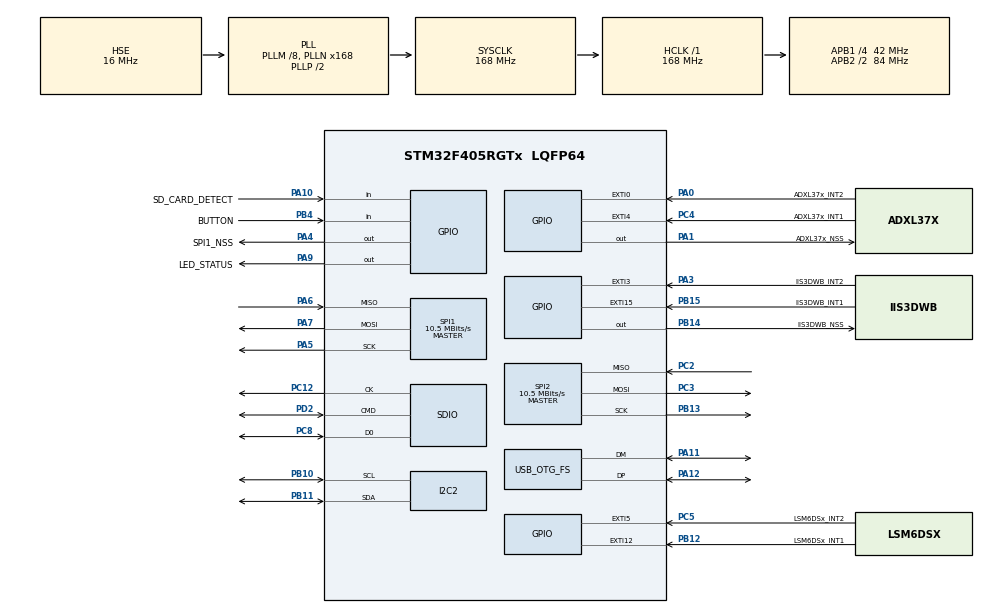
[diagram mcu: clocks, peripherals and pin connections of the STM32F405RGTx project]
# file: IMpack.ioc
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Dma.Request0=SDIO_RX
Dma.Request1=SDIO_TX
Dma.SDIO_RX.0.Direction=DMA_PERIPH_TO_MEMORY
Dma.SDIO_RX.0.FIFOMode=DMA_FIFOMODE_ENABLE
Dma.SDIO_RX.0.FIFOThreshold=DMA_FIFO_THRESHOLD_FULL
Dma.SDIO_RX.0.Instance=DMA2_Stream3
Dma.SDIO_RX.0.MemBurst=DMA_MBURST_INC4
Dma.SDIO_RX.0.MemDataAlignment=DMA_MDATAALIGN_WORD
Dma.SDIO_RX.0.MemInc=DMA_MINC_ENABLE
Dma.SDIO_RX.0.Mode=DMA_PFCTRL
Dma.SDIO_RX.0.PeriphBurst=DMA_PBURST_INC4
Dma.SDIO_RX.0.PeriphDataAlignment=DMA_PDATAALIGN_WORD
Dma.SDIO_RX.0.PeriphInc=DMA_PINC_DISABLE
Dma.SDIO_RX.0.Priority=DMA_PRIORITY_MEDIUM
Dma.SDIO_TX.1.Direction=DMA_MEMORY_TO_PERIPH
Dma.SDIO_TX.1.FIFOMode=DMA_FIFOMODE_ENABLE
Dma.SDIO_TX.1.FIFOThreshold=DMA_FIFO_THRESHOLD_FULL
Dma.SDIO_TX.1.Instance=DMA2_Stream6
Dma.SDIO_TX.1.MemBurst=DMA_MBURST_INC4
Dma.SDIO_TX.1.MemDataAlignment=DMA_MDATAALIGN_WORD
Dma.SDIO_TX.1.MemInc=DMA_MINC_ENABLE
Dma.SDIO_TX.1.Mode=DMA_PFCTRL
Dma.SDIO_TX.1.PeriphBurst=DMA_PBURST_INC4
Dma.SDIO_TX.1.PeriphDataAlignment=DMA_PDATAALIGN_WORD
Dma.SDIO_TX.1.PeriphInc=DMA_PINC_DISABLE
Dma.SDIO_TX.1.Priority=DMA_PRIORITY_MEDIUM
FATFS.BSP.number=1
FATFS.USE_DMA_CODE_SD=1
FATFS._FS_LOCK=0
FATFS0.BSP.STBoard=false
FATFS0.BSP.api=Unknown
FATFS0.BSP.instance=PA10
FATFS0.BSP.ip=GPIO
FATFS0.BSP.mode=Input
FATFS0.BSP.name=Detect_SDIO
FATFS0.BSP.solution=PA10
Mcu.Family=STM32F4
Mcu.Name=STM32F405RGTx
Mcu.Package=LQFP64
NVIC.DMA2_Stream3_IRQn=true\:2\:2\:true\:false\:true\:true\:true\:true
NVIC.DMA2_Stream6_IRQn=true\:2\:2\:true\:false\:true\:true\:true\:true
NVIC.EXTI15_10_IRQn=true\:0\:0\:true\:false\:true\:true\:true\:true
NVIC.EXTI4_IRQn=true\:0\:0\:true\:false\:true\:true\:true\:true
NVIC.EXTI9_5_IRQn=true\:0\:0\:true\:false\:true\:true\:true\:true
NVIC.PriorityGroup=NVIC_PRIORITYGROUP_2
NVIC.SDIO_IRQn=true\:2\:2\:true\:false\:true\:true\:true\:true
NVIC.TIM3_IRQn=true\:2\:2\:true\:false\:true\:true\:true\:true
PA0-WKUP.GPIO_Label=ADXL37x_INT2
PA0-WKUP.Signal=GPXTI0
PA1.GPIO_Label=ADXL37x_NSS
PA1.GPIO_Speed=GPIO_SPEED_FREQ_VERY_HIGH
PA1.PinState=GPIO_PIN_SET
PA1.Signal=GPIO_Output
PA10.GPIO_Label=SD_CARD_DETECT
PA10.Signal=GPIO_Input
PA11.Mode=Device_Only
PA11.Signal=USB_OTG_FS_DM
PA12.Mode=Device_Only
PA12.Signal=USB_OTG_FS_DP
PA13.Mode=Trace_Asynchronous_SW
PA13.Signal=SYS_JTMS-SWDIO
PA14.Mode=Trace_Asynchronous_SW
PA14.Signal=SYS_JTCK-SWCLK
PA3.GPIO_Label=IIS3DWB_INT2
PA3.Signal=GPXTI3
PA4.GPIO_Label=SPI1_NSS
PA4.GPIO_Speed=GPIO_SPEED_FREQ_VERY_HIGH
PA4.PinState=GPIO_PIN_SET
PA4.Signal=GPIO_Output
PA5.Mode=Full_Duplex_Master
PA5.Signal=SPI1_SCK
PA6.Mode=Full_Duplex_Master
PA6.Signal=SPI1_MISO
PA7.Mode=Full_Duplex_Master
PA7.Signal=SPI1_MOSI
PA9.GPIO_Label=LED_STATUS
PA9.PinState=GPIO_PIN_RESET
PA9.Signal=GPIO_Output
PB10.GPIO_Pu=GPIO_NOPULL
PB10.Mode=I2C
PB10.Signal=I2C2_SCL
PB11.GPIO_Pu=GPIO_NOPULL
PB11.Mode=I2C
PB11.Signal=I2C2_SDA
PB12.GPIO_Label=LSM6DSx_INT1
PB12.Signal=GPXTI12
PB13.Mode=Full_Duplex_Master
PB13.Signal=SPI2_SCK
PB14.GPIO_Label=IIS3DWB_NSS
PB14.GPIO_Speed=GPIO_SPEED_FREQ_VERY_HIGH
PB14.PinState=GPIO_PIN_SET
PB14.Signal=GPIO_Output
PB15.GPIO_Label=IIS3DWB_INT1
PB15.Signal=GPXTI15
PB3.Mode=Trace_Asynchronous_SW
PB3.Signal=SYS_JTDO-SWO
PB4.GPIO_Label=BUTTON
PB4.Signal=GPIO_Input
PC10.Signal=SDIO_D2
PC11.Signal=SDIO_D3
PC12.GPIO_PuPd=GPIO_NOPULL
PC12.Mode=SD_1_bit
PC12.Signal=SDIO_CK
PC2.Mode=Full_Duplex_Master
PC2.Signal=SPI2_MISO
PC3.Mode=Full_Duplex_Master
PC3.Signal=SPI2_MOSI
PC4.GPIO_Label=ADXL37x_INT1
PC4.Signal=GPXTI4
PC5.GPIO_Label=LSM6DSx_INT2
PC5.Signal=GPXTI5
PC8.GPIO_PuPd=GPIO_NOPULL
PC8.Mode=SD_1_bit
PC8.Signal=SDIO_D0
PC9.Signal=SDIO_D1
PD2.GPIO_PuPd=GPIO_NOPULL
PD2.Mode=SD_1_bit
PD2.Signal=SDIO_CMD
PH0-OSC_IN.Mode=HSE-External-Oscillator
PH0-OSC_IN.Signal=RCC_OSC_IN
PH1-OSC_OUT.Mode=HSE-External-Oscillator
PH1-OSC_OUT.Signal=RCC_OSC_OUT
ProjectManager.HeapSize=0x800
ProjectManager.StackSize=0x1600
ProjectManager.TargetToolchain=STM32CubeIDE
RCC.48MHZClocksFreq_Value=48000000
RCC.AHBFreq_Value=168000000
RCC.APB1CLKDivider=RCC_HCLK_DIV4
RCC.APB1Freq_Value=42000000
RCC.APB1TimFreq_Value=84000000
RCC.APB2CLKDivider=RCC_HCLK_DIV2
RCC.APB2Freq_Value=84000000
RCC.APB2TimFreq_Value=168000000
RCC.CortexFreq_Value=168000000
RCC.HCLKFreq_Value=168000000
RCC.HSE_VALUE=16000000
RCC.HSI_VALUE=16000000
RCC.LSE_VALUE=32768
RCC.PLLM=8
RCC.PLLN=168
RCC.PLLQ=7
RCC.SYSCLKFreq_VALUE=168000000
RCC.SYSCLKSource=RCC_SYSCLKSOURCE_PLLCLK
RCC.VCOOutputFreq_Value=336000000
SDIO.ClockBypass=SDIO_CLOCK_BYPASS_DISABLE
SDIO.ClockDiv=0
SPI1.BaudRatePrescaler=SPI_BAUDRATEPRESCALER_8
SPI1.CalculateBaudRate=10.5 MBits/s
SPI1.Direction=SPI_DIRECTION_2LINES
SPI1.Mode=SPI_MODE_MASTER
SPI1.VirtualType=VM_MASTER
SPI2.BaudRatePrescaler=SPI_BAUDRATEPRESCALER_4
SPI2.CalculateBaudRate=10.5 MBits/s
SPI2.Direction=SPI_DIRECTION_2LINES
SPI2.Mode=SPI_MODE_MASTER
SPI2.VirtualType=VM_MASTER
TIM2.Prescaler=83
TIM3.Period=840-1
USB_OTG_FS.VirtualMode=Device_Only
VP_FATFS_VS_SDIO.Mode=SDIO
VP_TIM2_VS_ClockSourceINT.Mode=Internal
VP_TIM3_VS_ClockSourceINT.Mode=Internal
board=custom

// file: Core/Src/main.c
/* USER CODE BEGIN Header */
/**
  ******************************************************************************
  * @file           : main.c
  * @brief          : Main program body
  ******************************************************************************
  * @attention
  *
  * Copyright (c) 2024 STMicroelectronics.
  * All rights reserved.
  *
  * This software is licensed under terms that can be found in the LICENSE file
  * in the root directory of this software component.
  * If no LICENSE file comes with this software, it is provided AS-IS.
  *
  ******************************************************************************
  */
/* USER CODE END Header */
#include "main.h"
#include "fatfs.h"

/* USER CODE BEGIN Includes */
#include "app.h"
/* USER CODE END Includes */

I2C_HandleTypeDef hi2c2;

SD_HandleTypeDef hsd;
DMA_HandleTypeDef hdma_sdio_rx;
DMA_HandleTypeDef hdma_sdio_tx;

SPI_HandleTypeDef hspi1;
SPI_HandleTypeDef hspi2;

TIM_HandleTypeDef htim2;
TIM_HandleTypeDef htim3;

PCD_HandleTypeDef hpcd_USB_OTG_FS;

void SystemClock_Config(void);
static void MX_GPIO_Init(void);
static void MX_DMA_Init(void);
static void MX_SPI1_Init(void);
static void MX_SDIO_SD_Init(void);
static void MX_SPI2_Init(void);
static void MX_TIM2_Init(void);
static void MX_I2C2_Init(void);
static void MX_TIM3_Init(void);
static void MX_USB_OTG_FS_PCD_Init(void);

/* USER CODE BEGIN 0 */
void HAL_GPIO_EXTI_Callback(uint16_t GPIO_Pin)
{
	App_PinInterrupt(GPIO_Pin);  /* call our application interrupt handler */
}

void HAL_TIM_PeriodElapsedCallback(TIM_HandleTypeDef* htim)
{
    App_TimerInterrupt();
}

/* USER CODE END 0 */

int main(void)
{

  /* MCU Configuration--------------------------------------------------------*/

  /* Reset of all peripherals, Initializes the Flash interface and the Systick. */
  HAL_Init();

  /* Configure the system clock */
  SystemClock_Config();

  /* Initialize all configured peripherals */
  MX_GPIO_Init();
  MX_DMA_Init();
  MX_SPI1_Init();
  MX_SDIO_SD_Init();
  MX_FATFS_Init();
  MX_SPI2_Init();
  MX_TIM2_Init();
  MX_I2C2_Init();
  MX_TIM3_Init();
  MX_USB_OTG_FS_PCD_Init();
  /* USER CODE BEGIN 2 */

  /* start the timer to measure sampling time */
  HAL_TIM_Base_Start(&htim2);

  /* set up our application */
  App_Setup(&hsd, &hspi1, &hspi2, &hspi2, &(TIM2->CNT));

  /* start the timer for the SPI communications thread */
  HAL_TIM_Base_Start_IT(&htim3);

  /* USER CODE END 2 */

  /* Infinite loop */
  /* USER CODE BEGIN WHILE */
  while (1)
  {

	App_Loop();

    /* USER CODE END WHILE */

  }
}

void SystemClock_Config(void)
{
  RCC_OscInitTypeDef RCC_OscInitStruct = {0};
  RCC_ClkInitTypeDef RCC_ClkInitStruct = {0};

  /** Configure the main internal regulator output voltage
  */
  __HAL_RCC_PWR_CLK_ENABLE();
  __HAL_PWR_VOLTAGESCALING_CONFIG(PWR_REGULATOR_VOLTAGE_SCALE1);

  /** Initializes the RCC Oscillators according to the specified parameters
  * in the RCC_OscInitTypeDef structure.
  */
  RCC_OscInitStruct.OscillatorType = RCC_OSCILLATORTYPE_HSE;
  RCC_OscInitStruct.HSEState = RCC_HSE_ON;
  RCC_OscInitStruct.PLL.PLLState = RCC_PLL_ON;
  RCC_OscInitStruct.PLL.PLLSource = RCC_PLLSOURCE_HSE;
  RCC_OscInitStruct.PLL.PLLM = 8;
  RCC_OscInitStruct.PLL.PLLN = 168;
  RCC_OscInitStruct.PLL.PLLP = RCC_PLLP_DIV2;
  RCC_OscInitStruct.PLL.PLLQ = 7;
  if (HAL_RCC_OscConfig(&RCC_OscInitStruct) != HAL_OK)
  {
    Error_Handler();
  }

  /** Initializes the CPU, AHB and APB buses clocks
  */
  RCC_ClkInitStruct.ClockType = RCC_CLOCKTYPE_HCLK|RCC_CLOCKTYPE_SYSCLK
                              |RCC_CLOCKTYPE_PCLK1|RCC_CLOCKTYPE_PCLK2;
  RCC_ClkInitStruct.SYSCLKSource = RCC_SYSCLKSOURCE_PLLCLK;
  RCC_ClkInitStruct.AHBCLKDivider = RCC_SYSCLK_DIV1;
  RCC_ClkInitStruct.APB1CLKDivider = RCC_HCLK_DIV4;
  RCC_ClkInitStruct.APB2CLKDivider = RCC_HCLK_DIV2;

  if (HAL_RCC_ClockConfig(&RCC_ClkInitStruct, FLASH_LATENCY_5) != HAL_OK)
  {
    Error_Handler();
  }
}

static void MX_I2C2_Init(void)
{

  hi2c2.Instance = I2C2;
  hi2c2.Init.ClockSpeed = 100000;
  hi2c2.Init.DutyCycle = I2C_DUTYCYCLE_2;
  hi2c2.Init.OwnAddress1 = 0;
  hi2c2.Init.AddressingMode = I2C_ADDRESSINGMODE_7BIT;
  hi2c2.Init.DualAddressMode = I2C_DUALADDRESS_DISABLE;
  hi2c2.Init.OwnAddress2 = 0;
  hi2c2.Init.GeneralCallMode = I2C_GENERALCALL_DISABLE;
  hi2c2.Init.NoStretchMode = I2C_NOSTRETCH_DISABLE;
  if (HAL_I2C_Init(&hi2c2) != HAL_OK)
  {
    Error_Handler();
  }

}

static void MX_SDIO_SD_Init(void)
{

  hsd.Instance = SDIO;
  hsd.Init.ClockEdge = SDIO_CLOCK_EDGE_RISING;
  hsd.Init.ClockBypass = SDIO_CLOCK_BYPASS_DISABLE;
  hsd.Init.ClockPowerSave = SDIO_CLOCK_POWER_SAVE_DISABLE;
  hsd.Init.BusWide = SDIO_BUS_WIDE_1B;
  hsd.Init.HardwareFlowControl = SDIO_HARDWARE_FLOW_CONTROL_DISABLE;
  hsd.Init.ClockDiv = 0;

}

static void MX_SPI1_Init(void)
{

  /* SPI1 parameter configuration*/
  hspi1.Instance = SPI1;
  hspi1.Init.Mode = SPI_MODE_MASTER;
  hspi1.Init.Direction = SPI_DIRECTION_2LINES;
  hspi1.Init.DataSize = SPI_DATASIZE_8BIT;
  hspi1.Init.CLKPolarity = SPI_POLARITY_LOW;
  hspi1.Init.CLKPhase = SPI_PHASE_1EDGE;
  hspi1.Init.NSS = SPI_NSS_SOFT;
  hspi1.Init.BaudRatePrescaler = SPI_BAUDRATEPRESCALER_8;
  hspi1.Init.FirstBit = SPI_FIRSTBIT_MSB;
  hspi1.Init.TIMode = SPI_TIMODE_DISABLE;
  hspi1.Init.CRCCalculation = SPI_CRCCALCULATION_DISABLE;
  hspi1.Init.CRCPolynomial = 10;
  if (HAL_SPI_Init(&hspi1) != HAL_OK)
  {
    Error_Handler();
  }

}

static void MX_SPI2_Init(void)
{

  /* SPI2 parameter configuration*/
  hspi2.Instance = SPI2;
  hspi2.Init.Mode = SPI_MODE_MASTER;
  hspi2.Init.Direction = SPI_DIRECTION_2LINES;
  hspi2.Init.DataSize = SPI_DATASIZE_8BIT;
  hspi2.Init.CLKPolarity = SPI_POLARITY_LOW;
  hspi2.Init.CLKPhase = SPI_PHASE_1EDGE;
  hspi2.Init.NSS = SPI_NSS_SOFT;
  hspi2.Init.BaudRatePrescaler = SPI_BAUDRATEPRESCALER_4;
  hspi2.Init.FirstBit = SPI_FIRSTBIT_MSB;
  hspi2.Init.TIMode = SPI_TIMODE_DISABLE;
  hspi2.Init.CRCCalculation = SPI_CRCCALCULATION_DISABLE;
  hspi2.Init.CRCPolynomial = 10;
  if (HAL_SPI_Init(&hspi2) != HAL_OK)
  {
    Error_Handler();
  }

}

static void MX_TIM2_Init(void)
{

  TIM_ClockConfigTypeDef sClockSourceConfig = {0};
  TIM_MasterConfigTypeDef sMasterConfig = {0};

  htim2.Instance = TIM2;
  htim2.Init.Prescaler = 83;
  htim2.Init.CounterMode = TIM_COUNTERMODE_UP;
  htim2.Init.Period = 4294967295;
  htim2.Init.ClockDivision = TIM_CLOCKDIVISION_DIV1;
  htim2.Init.AutoReloadPreload = TIM_AUTORELOAD_PRELOAD_DISABLE;
  if (HAL_TIM_Base_Init(&htim2) != HAL_OK)
  {
    Error_Handler();
  }
  sClockSourceConfig.ClockSource = TIM_CLOCKSOURCE_INTERNAL;
  if (HAL_TIM_ConfigClockSource(&htim2, &sClockSourceConfig) != HAL_OK)
  {
    Error_Handler();
  }
  sMasterConfig.MasterOutputTrigger = TIM_TRGO_RESET;
  sMasterConfig.MasterSlaveMode = TIM_MASTERSLAVEMODE_DISABLE;
  if (HAL_TIMEx_MasterConfigSynchronization(&htim2, &sMasterConfig) != HAL_OK)
  {
    Error_Handler();
  }

}

static void MX_TIM3_Init(void)
{

  TIM_ClockConfigTypeDef sClockSourceConfig = {0};
  TIM_MasterConfigTypeDef sMasterConfig = {0};

  htim3.Instance = TIM3;
  htim3.Init.Prescaler = 0;
  htim3.Init.CounterMode = TIM_COUNTERMODE_UP;
  htim3.Init.Period = 840-1;
  htim3.Init.ClockDivision = TIM_CLOCKDIVISION_DIV1;
  htim3.Init.AutoReloadPreload = TIM_AUTORELOAD_PRELOAD_DISABLE;
  if (HAL_TIM_Base_Init(&htim3) != HAL_OK)
  {
    Error_Handler();
  }
  sClockSourceConfig.ClockSource = TIM_CLOCKSOURCE_INTERNAL;
  if (HAL_TIM_ConfigClockSource(&htim3, &sClockSourceConfig) != HAL_OK)
  {
    Error_Handler();
  }
  sMasterConfig.MasterOutputTrigger = TIM_TRGO_RESET;
  sMasterConfig.MasterSlaveMode = TIM_MASTERSLAVEMODE_DISABLE;
  if (HAL_TIMEx_MasterConfigSynchronization(&htim3, &sMasterConfig) != HAL_OK)
  {
    Error_Handler();
  }

}

static void MX_USB_OTG_FS_PCD_Init(void)
{

  hpcd_USB_OTG_FS.Instance = USB_OTG_FS;
  hpcd_USB_OTG_FS.Init.dev_endpoints = 4;
  hpcd_USB_OTG_FS.Init.speed = PCD_SPEED_FULL;
  hpcd_USB_OTG_FS.Init.dma_enable = DISABLE;
  hpcd_USB_OTG_FS.Init.phy_itface = PCD_PHY_EMBEDDED;
  hpcd_USB_OTG_FS.Init.Sof_enable = DISABLE;
  hpcd_USB_OTG_FS.Init.low_power_enable = DISABLE;
  hpcd_USB_OTG_FS.Init.lpm_enable = DISABLE;
  hpcd_USB_OTG_FS.Init.vbus_sensing_enable = DISABLE;
  hpcd_USB_OTG_FS.Init.use_dedicated_ep1 = DISABLE;
  if (HAL_PCD_Init(&hpcd_USB_OTG_FS) != HAL_OK)
  {
    Error_Handler();
  }

}

static void MX_DMA_Init(void)
{

  /* DMA controller clock enable */
  __HAL_RCC_DMA2_CLK_ENABLE();

  /* DMA interrupt init */
  /* DMA2_Stream3_IRQn interrupt configuration */
  HAL_NVIC_SetPriority(DMA2_Stream3_IRQn, 2, 2);
  HAL_NVIC_EnableIRQ(DMA2_Stream3_IRQn);
  /* DMA2_Stream6_IRQn interrupt configuration */
  HAL_NVIC_SetPriority(DMA2_Stream6_IRQn, 2, 2);
  HAL_NVIC_EnableIRQ(DMA2_Stream6_IRQn);

}

static void MX_GPIO_Init(void)
{
  GPIO_InitTypeDef GPIO_InitStruct = {0};

  /* GPIO Ports Clock Enable */
  __HAL_RCC_GPIOH_CLK_ENABLE();
  __HAL_RCC_GPIOC_CLK_ENABLE();
  __HAL_RCC_GPIOA_CLK_ENABLE();
  __HAL_RCC_GPIOB_CLK_ENABLE();
  __HAL_RCC_GPIOD_CLK_ENABLE();

  /*Configure GPIO pin Output Level */
  HAL_GPIO_WritePin(GPIOA, ADXL37x_NSS_Pin|SPI1_NSS_Pin, GPIO_PIN_SET);

  /*Configure GPIO pin Output Level */
  HAL_GPIO_WritePin(IIS3DWB_NSS_GPIO_Port, IIS3DWB_NSS_Pin, GPIO_PIN_SET);

  /*Configure GPIO pin Output Level */
  HAL_GPIO_WritePin(LED_STATUS_GPIO_Port, LED_STATUS_Pin, GPIO_PIN_RESET);

  /*Configure GPIO pins : ADXL37x_INT2_Pin IIS3DWB_INT2_Pin */
  GPIO_InitStruct.Pin = ADXL37x_INT2_Pin|IIS3DWB_INT2_Pin;
  GPIO_InitStruct.Mode = GPIO_MODE_IT_RISING;
  GPIO_InitStruct.Pull = GPIO_NOPULL;
  HAL_GPIO_Init(GPIOA, &GPIO_InitStruct);

  /*Configure GPIO pins : ADXL37x_NSS_Pin SPI1_NSS_Pin */
  GPIO_InitStruct.Pin = ADXL37x_NSS_Pin|SPI1_NSS_Pin;
  GPIO_InitStruct.Mode = GPIO_MODE_OUTPUT_PP;
  GPIO_InitStruct.Pull = GPIO_NOPULL;
  GPIO_InitStruct.Speed = GPIO_SPEED_FREQ_VERY_HIGH;
  HAL_GPIO_Init(GPIOA, &GPIO_InitStruct);

  /*Configure GPIO pins : ADXL37x_INT1_Pin LSM6DSx_INT2_Pin */
  GPIO_InitStruct.Pin = ADXL37x_INT1_Pin|LSM6DSx_INT2_Pin;
  GPIO_InitStruct.Mode = GPIO_MODE_IT_RISING;
  GPIO_InitStruct.Pull = GPIO_NOPULL;
  HAL_GPIO_Init(GPIOC, &GPIO_InitStruct);

  /*Configure GPIO pins : LSM6DSx_INT1_Pin IIS3DWB_INT1_Pin */
  GPIO_InitStruct.Pin = LSM6DSx_INT1_Pin|IIS3DWB_INT1_Pin;
  GPIO_InitStruct.Mode = GPIO_MODE_IT_RISING;
  GPIO_InitStruct.Pull = GPIO_NOPULL;
  HAL_GPIO_Init(GPIOB, &GPIO_InitStruct);

  /*Configure GPIO pin : IIS3DWB_NSS_Pin */
  GPIO_InitStruct.Pin = IIS3DWB_NSS_Pin;
  GPIO_InitStruct.Mode = GPIO_MODE_OUTPUT_PP;
  GPIO_InitStruct.Pull = GPIO_NOPULL;
  GPIO_InitStruct.Speed = GPIO_SPEED_FREQ_VERY_HIGH;
  HAL_GPIO_Init(IIS3DWB_NSS_GPIO_Port, &GPIO_InitStruct);

  /*Configure GPIO pin : LED_STATUS_Pin */
  GPIO_InitStruct.Pin = LED_STATUS_Pin;
  GPIO_InitStruct.Mode = GPIO_MODE_OUTPUT_PP;
  GPIO_InitStruct.Pull = GPIO_NOPULL;
  GPIO_InitStruct.Speed = GPIO_SPEED_FREQ_LOW;
  HAL_GPIO_Init(LED_STATUS_GPIO_Port, &GPIO_InitStruct);

  /*Configure GPIO pin : SD_CARD_DETECT_Pin */
  GPIO_InitStruct.Pin = SD_CARD_DETECT_Pin;
  GPIO_InitStruct.Mode = GPIO_MODE_INPUT;
  GPIO_InitStruct.Pull = GPIO_NOPULL;
  HAL_GPIO_Init(SD_CARD_DETECT_GPIO_Port, &GPIO_InitStruct);

  /*Configure GPIO pin : BUTTON_Pin */
  GPIO_InitStruct.Pin = BUTTON_Pin;
  GPIO_InitStruct.Mode = GPIO_MODE_INPUT;
  GPIO_InitStruct.Pull = GPIO_NOPULL;
  HAL_GPIO_Init(BUTTON_GPIO_Port, &GPIO_InitStruct);

  /* EXTI interrupt init*/
  HAL_NVIC_SetPriority(EXTI4_IRQn, 0, 0);
  HAL_NVIC_EnableIRQ(EXTI4_IRQn);

  HAL_NVIC_SetPriority(EXTI9_5_IRQn, 0, 0);
  HAL_NVIC_EnableIRQ(EXTI9_5_IRQn);

  HAL_NVIC_SetPriority(EXTI15_10_IRQn, 0, 0);
  HAL_NVIC_EnableIRQ(EXTI15_10_IRQn);

}

void Error_Handler(void)
{
  __disable_irq();
  while (1)
  {
  }
}
